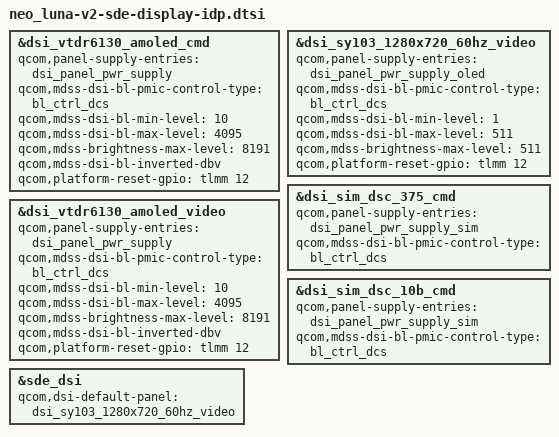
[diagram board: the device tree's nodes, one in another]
#include "neo_luna-v2-sde-display.dtsi"

&dsi_vtdr6130_amoled_cmd {
	qcom,panel-supply-entries = <&dsi_panel_pwr_supply>;
	qcom,mdss-dsi-bl-pmic-control-type = "bl_ctrl_dcs";
	qcom,mdss-dsi-bl-min-level = <10>;
	qcom,mdss-dsi-bl-max-level = <4095>;
	qcom,mdss-brightness-max-level = <8191>;
	qcom,mdss-dsi-bl-inverted-dbv;
	qcom,platform-reset-gpio = <&tlmm 12 0>;
};

&dsi_vtdr6130_amoled_video {
	qcom,panel-supply-entries = <&dsi_panel_pwr_supply>;
	qcom,mdss-dsi-bl-pmic-control-type = "bl_ctrl_dcs";
	qcom,mdss-dsi-bl-min-level = <10>;
	qcom,mdss-dsi-bl-max-level = <4095>;
	qcom,mdss-brightness-max-level = <8191>;
	qcom,mdss-dsi-bl-inverted-dbv;
	qcom,platform-reset-gpio = <&tlmm 12 0>;
};

&dsi_sy103_1280x720_60hz_video {
	qcom,panel-supply-entries = <&dsi_panel_pwr_supply_oled>;
	qcom,mdss-dsi-bl-pmic-control-type = "bl_ctrl_dcs";
	qcom,mdss-dsi-bl-min-level = <1>;
	qcom,mdss-dsi-bl-max-level = <511>;
	qcom,mdss-brightness-max-level = <511>;
	qcom,platform-reset-gpio = <&tlmm 12 0>;
};

&dsi_sim_dsc_375_cmd {
	qcom,panel-supply-entries = <&dsi_panel_pwr_supply_sim>;
	qcom,mdss-dsi-bl-pmic-control-type = "bl_ctrl_dcs";
};

&dsi_sim_dsc_10b_cmd {
	qcom,panel-supply-entries = <&dsi_panel_pwr_supply_sim>;
	qcom,mdss-dsi-bl-pmic-control-type = "bl_ctrl_dcs";
};

&sde_dsi {
	qcom,dsi-default-panel = <&dsi_sy103_1280x720_60hz_video>;
};
